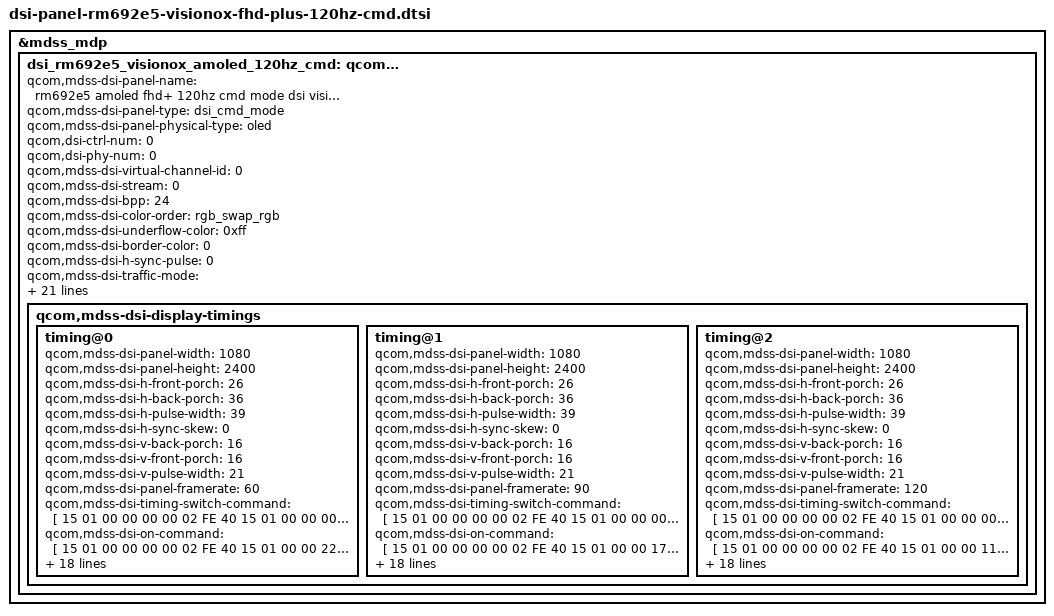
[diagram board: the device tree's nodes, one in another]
&mdss_mdp {
	dsi_rm692e5_visionox_amoled_120hz_cmd:
		qcom,mdss_dsi_rm692e5_visionox_amoled_120hz_cmd {
		qcom,mdss-dsi-panel-name =
		"rm692e5 amoled fhd+ 120hz cmd mode dsi visionox panel";
		qcom,mdss-dsi-panel-type = "dsi_cmd_mode";
		qcom,mdss-dsi-panel-physical-type = "oled";
		qcom,dsi-ctrl-num = <0>;
		qcom,dsi-phy-num = <0>;

		qcom,mdss-dsi-virtual-channel-id = <0>;
		qcom,mdss-dsi-stream = <0>;
		qcom,mdss-dsi-bpp = <24>;
		qcom,mdss-dsi-color-order = "rgb_swap_rgb";
		qcom,mdss-dsi-underflow-color = <0xff>;
		qcom,mdss-dsi-border-color = <0>;
		qcom,mdss-dsi-h-sync-pulse = <0>;
		qcom,mdss-dsi-traffic-mode = "non_burst_sync_event";
		qcom,mdss-dsi-lane-map = "lane_map_0123";
		qcom,mdss-dsi-bllp-eof-power-mode;
		qcom,mdss-dsi-bllp-power-mode;
		qcom,mdss-dsi-tx-eot-append;
		qcom,mdss-dsi-lane-0-state;
		qcom,mdss-dsi-lane-1-state;
		qcom,mdss-dsi-lane-2-state;
		qcom,mdss-dsi-lane-3-state;
		qcom,mdss-dsi-dma-trigger = "trigger_sw";
		qcom,mdss-dsi-mdp-trigger = "none";
		qcom,mdss-dsi-lp11-init;
		qcom,mdss-dsi-reset-sequence = <1 10>, <0 1>, <1 32>;
		qcom,mdss-dsi-te-pin-select = <1>;
		qcom,mdss-dsi-wr-mem-start = <0x2c>;
		qcom,mdss-dsi-wr-mem-continue = <0x3c>;
		qcom,mdss-dsi-te-dcs-command = <1>;
		qcom,mdss-dsi-te-check-enable;
		qcom,mdss-dsi-te-using-te-pin;
		qcom,fod-dim-lut = <
		/* brightness, alpha */
			0	255
			1	254
			2	253
			4	249
			6	240
			12	245
			14	243
			28	242
			42	241
			57	239
			71	238
			85	237
			100	236
			112	234
			125	233
			137	232
			150	231
			162	229
			175	228
			187	227
			200	225
			221	224
			243	223
			265	222
			286	220
			308	219
			330	218
			351	217
			373	215
			395	214
			417	213
			438	211
			460	210
			482	209
			503	208
			525	206
			547	205
			569	204
			590	203
			612	201
			634	200
			655	199
			677	197
			699	196
			721	195
			742	194
			764	192
			786	191
			807	190
			829	189
			851	187
			873	186
			894	185
			916	183
			938	182
			959	181
			981	180
			1003	178
			1024	177
			1046	176
			1068	175
			1090	173
			1111	172
			1133	171
			1155	169
			1176	168
			1198	167
			1220	166
			1242	164
			1263	163
			1285	162
			1307	161
			1328	159
			1350	158
			1372	157
			1394	155
			1415	154
			1437	153
			1459	152
			1480	150
			1502	149
			1524	148
			1546	147
			1567	145
			1589	144
			1611	143
			1632	141
			1654	140
			1676	139
			1698	138
			1719	136
			1741	135
			1763	134
			1784	133
			1806	131
			1828	130
			1849	129
			1871	127
			1893	126
			1915	125
			1936	124
			1958	122
			1980	121
			2001	120
			2023	119
			2045	117
			2067	116
			2088	115
			2110	113
			2132	112
			2153	111
			2175	110
			2197	108
			2219	107
			2240	106
			2262	105
			2284	103
			2305	102
			2327	101
			2349	99
			2371	98
			2392	97
			2414	96
			2436	94
			2457	93
			2479	92
			2501	91
			2523	89
			2544	88
			2566	87
			2588	85
			2609	84
			2631	83
			2653	82
			2674	80
			2696	79
			2718	78
			2740	77
			2761	75
			2783	74
			2805	73
			2826	71
			2848	70
			2870	69
			2892	68
			2913	66
			2935	65
			2957	64
			2978	63
			3000	61
			3022	60
			3044	59
			3065	57
			3087	56
			3109	55
			3130	54
			3152	52
			3174	51
			3196	50
			3217	49
			3239	47
			3261	46
			3282	45
			3304	43
			3326	42
			3348	41
			3369	40
			3391	38
			3413	37
			3434	36
			3456	35
			3478	33
			3499	32
			3521	31
			3541	29
		>;
		qcom,mdss-dsi-display-timings {
			timing@0 {
				qcom,mdss-dsi-panel-width = <1080>;
				qcom,mdss-dsi-panel-height = <2400>;
				qcom,mdss-dsi-h-front-porch = <26>;
				qcom,mdss-dsi-h-back-porch = <36>;
				qcom,mdss-dsi-h-pulse-width = <39>;
				qcom,mdss-dsi-h-sync-skew = <0>;
				qcom,mdss-dsi-v-back-porch = <16>;
				qcom,mdss-dsi-v-front-porch = <16>;
				qcom,mdss-dsi-v-pulse-width = <21>;
				qcom,mdss-dsi-panel-framerate = <60>;

				qcom,mdss-dsi-timing-switch-command = [
						15 01 00 00 00 00 02 FE 40
						15 01 00 00 00 00 02 BD 00
						15 01 00 00 22 00 02 FE 00
				];

				qcom,mdss-dsi-on-command = [
						15 01 00 00 00 00 02 FE 40
						15 01 00 00 22 00 02 BD 00
						15 01 00 00 00 00 02 FE D2
						15 01 00 00 00 00 02 50 11
						15 01 00 00 00 00 02 51 AB
						15 01 00 00 00 00 02 52 30
						15 01 00 00 00 00 02 53 09
						15 01 00 00 00 00 02 54 60
						15 01 00 00 00 00 02 55 04
						15 01 00 00 00 00 02 56 38
						15 01 00 00 00 00 02 58 00
						15 01 00 00 00 00 02 59 14
						15 01 00 00 00 00 02 5A 02
						15 01 00 00 00 00 02 5B 1C
						15 01 00 00 00 00 02 5C 02
						15 01 00 00 00 00 02 5D 00
						15 01 00 00 00 00 02 5E 20
						15 01 00 00 00 00 02 5F 01
						15 01 00 00 00 00 02 60 e8
						15 01 00 00 00 00 02 61 00
						15 01 00 00 00 00 02 62 07
						15 01 00 00 00 00 02 63 0C
						15 01 00 00 00 00 02 64 05
						15 01 00 00 00 00 02 65 0E
						15 01 00 00 00 00 02 66 05
						15 01 00 00 00 00 02 67 16
						15 01 00 00 00 00 02 68 18
						15 01 00 00 00 00 02 69 00
						15 01 00 00 00 00 02 6A 10
						15 01 00 00 00 00 02 6B F0
						15 01 00 00 00 00 02 6C 07
						15 01 00 00 00 00 02 6D 10
						15 01 00 00 00 00 02 6E 20
						15 01 00 00 00 00 02 6F 00
						15 01 00 00 00 00 02 70 06
						15 01 00 00 00 00 02 71 0F
						15 01 00 00 00 00 02 72 0F
						15 01 00 00 00 00 02 73 33
						15 01 00 00 00 00 02 74 0E
						15 01 00 00 00 00 02 75 1C
						15 01 00 00 00 00 02 76 2A
						15 01 00 00 00 00 02 77 38
						15 01 00 00 00 00 02 78 46
						15 01 00 00 00 00 02 79 54
						15 01 00 00 00 00 02 7A 62
						15 01 00 00 00 00 02 7B 69
						15 01 00 00 00 00 02 7C 70
						15 01 00 00 00 00 02 7D 77
						15 01 00 00 00 00 02 7E 79
						15 01 00 00 00 00 02 7F 7B
						15 01 00 00 00 00 02 80 7D
						15 01 00 00 00 00 02 81 7E
						15 01 00 00 00 00 02 82 01
						15 01 00 00 00 00 02 83 02
						15 01 00 00 00 00 02 84 22
						15 01 00 00 00 00 02 85 00
						15 01 00 00 00 00 02 86 2A
						15 01 00 00 00 00 02 87 40
						15 01 00 00 00 00 02 88 2A
						15 01 00 00 00 00 02 89 BE
						15 01 00 00 00 00 02 8A 3A
						15 01 00 00 00 00 02 8B FC
						15 01 00 00 00 00 02 8C 3A
						15 01 00 00 00 00 02 8D FA
						15 01 00 00 00 00 02 8E 3A
						15 01 00 00 00 00 02 8F F8
						15 01 00 00 00 00 02 90 3B
						15 01 00 00 00 00 02 91 38
						15 01 00 00 00 00 02 92 3B
						15 01 00 00 00 00 02 93 78
						15 01 00 00 00 00 02 94 3B
						15 01 00 00 00 00 02 95 B6
						15 01 00 00 00 00 02 96 4B
						15 01 00 00 00 00 02 97 F6
						15 01 00 00 00 00 02 98 4C
						15 01 00 00 00 00 02 99 34
						15 01 00 00 00 00 02 9A 4C
						15 01 00 00 00 00 02 9B 74
						15 01 00 00 00 00 02 9C 5C
						15 01 00 00 00 00 02 9D 74
						15 01 00 00 00 00 02 9E 8C
						15 01 00 00 00 00 02 9F F4
						15 01 00 00 00 00 02 A2 02
						15 01 00 00 00 00 02 A3 1C
						15 01 00 00 00 00 02 A4 00
						15 01 00 00 00 00 02 A5 00
						15 01 00 00 00 00 02 A6 00
						15 01 00 00 00 00 02 A7 00
						15 01 00 00 00 00 02 A9 00
						15 01 00 00 00 00 02 AA 00
						15 01 00 00 00 00 02 A0 80
						15 01 00 00 00 00 02 FE A1
						15 01 00 00 00 00 02 CD 6B
						15 01 00 00 00 00 02 CE BB
						15 01 00 00 00 00 02 FE D1
						15 01 00 00 00 00 02 B4 01
						15 01 00 00 00 00 02 FE 38
						15 01 00 00 00 00 02 17 0F
						15 01 00 00 00 00 02 18 0F
						15 01 00 00 00 00 02 FE 00
						15 01 00 00 00 00 02 FA 01
						15 01 00 00 00 00 02 C2 08
						15 01 00 00 00 00 02 35 00
						15 01 00 00 00 00 03 51 0D BB
						05 01 00 00 32 00 02 11 00
						05 01 00 00 01 00 02 29 00];
				qcom,mdss-dsi-off-command = [
						05 01 00 00 01 00 02 28 00
						05 01 00 00 01 00 02 10 00];
				qcom,mdss-dsi-on-command-state = "dsi_lp_mode";
				qcom,mdss-dsi-off-command-state = "dsi_hs_mode";

				qcom,mdss-dsi-lp1-command = [
						15 01 00 00 00 00 02 FE 00
						05 01 00 00 00 00 01 39];
				qcom,mdss-dsi-lp1-command-state = "dsi_lp_mode";
				qcom,mdss-dsi-nolp-command = [
						15 01 00 00 00 00 02 FE 00
						05 01 00 00 00 00 01 38];
				qcom,mdss-dsi-nolp-command-state = "dsi_lp_mode";

				qcom,mdss-dsi-h-sync-pulse = <0>;
				qcom,compression-mode = "dsc";
				qcom,mdss-dsc-slice-height = <20>;
				qcom,mdss-dsc-slice-width = <540>;
				qcom,mdss-dsc-slice-per-pkt = <2>;
				qcom,mdss-dsc-bit-per-component = <10>;
				qcom,mdss-dsc-bit-per-pixel = <8>;
				qcom,mdss-dsc-block-prediction-enable;
			};
			timing@1 {
				qcom,mdss-dsi-panel-width = <1080>;
				qcom,mdss-dsi-panel-height = <2400>;
				qcom,mdss-dsi-h-front-porch = <26>;
				qcom,mdss-dsi-h-back-porch = <36>;
				qcom,mdss-dsi-h-pulse-width = <39>;
				qcom,mdss-dsi-h-sync-skew = <0>;
				qcom,mdss-dsi-v-back-porch = <16>;
				qcom,mdss-dsi-v-front-porch = <16>;
				qcom,mdss-dsi-v-pulse-width = <21>;
				qcom,mdss-dsi-panel-framerate = <90>;

				qcom,mdss-dsi-timing-switch-command = [
						15 01 00 00 00 00 02 FE 40
						15 01 00 00 00 00 02 BD 06
						15 01 00 00 17 00 02 FE 00
				];

				qcom,mdss-dsi-on-command = [
						15 01 00 00 00 00 02 FE 40
						15 01 00 00 17 00 02 BD 06
						15 01 00 00 00 00 02 FE D2
						15 01 00 00 00 00 02 50 11
						15 01 00 00 00 00 02 51 AB
						15 01 00 00 00 00 02 52 30
						15 01 00 00 00 00 02 53 09
						15 01 00 00 00 00 02 54 60
						15 01 00 00 00 00 02 55 04
						15 01 00 00 00 00 02 56 38
						15 01 00 00 00 00 02 58 00
						15 01 00 00 00 00 02 59 14
						15 01 00 00 00 00 02 5A 02
						15 01 00 00 00 00 02 5B 1C
						15 01 00 00 00 00 02 5C 02
						15 01 00 00 00 00 02 5D 00
						15 01 00 00 00 00 02 5E 20
						15 01 00 00 00 00 02 5F 01
						15 01 00 00 00 00 02 60 e8
						15 01 00 00 00 00 02 61 00
						15 01 00 00 00 00 02 62 07
						15 01 00 00 00 00 02 63 0C
						15 01 00 00 00 00 02 64 05
						15 01 00 00 00 00 02 65 0E
						15 01 00 00 00 00 02 66 05
						15 01 00 00 00 00 02 67 16
						15 01 00 00 00 00 02 68 18
						15 01 00 00 00 00 02 69 00
						15 01 00 00 00 00 02 6A 10
						15 01 00 00 00 00 02 6B F0
						15 01 00 00 00 00 02 6C 07
						15 01 00 00 00 00 02 6D 10
						15 01 00 00 00 00 02 6E 20
						15 01 00 00 00 00 02 6F 00
						15 01 00 00 00 00 02 70 06
						15 01 00 00 00 00 02 71 0F
						15 01 00 00 00 00 02 72 0F
						15 01 00 00 00 00 02 73 33
						15 01 00 00 00 00 02 74 0E
						15 01 00 00 00 00 02 75 1C
						15 01 00 00 00 00 02 76 2A
						15 01 00 00 00 00 02 77 38
						15 01 00 00 00 00 02 78 46
						15 01 00 00 00 00 02 79 54
						15 01 00 00 00 00 02 7A 62
						15 01 00 00 00 00 02 7B 69
						15 01 00 00 00 00 02 7C 70
						15 01 00 00 00 00 02 7D 77
						15 01 00 00 00 00 02 7E 79
						15 01 00 00 00 00 02 7F 7B
						15 01 00 00 00 00 02 80 7D
						15 01 00 00 00 00 02 81 7E
						15 01 00 00 00 00 02 82 01
						15 01 00 00 00 00 02 83 02
						15 01 00 00 00 00 02 84 22
						15 01 00 00 00 00 02 85 00
						15 01 00 00 00 00 02 86 2A
						15 01 00 00 00 00 02 87 40
						15 01 00 00 00 00 02 88 2A
						15 01 00 00 00 00 02 89 BE
						15 01 00 00 00 00 02 8A 3A
						15 01 00 00 00 00 02 8B FC
						15 01 00 00 00 00 02 8C 3A
						15 01 00 00 00 00 02 8D FA
						15 01 00 00 00 00 02 8E 3A
						15 01 00 00 00 00 02 8F F8
						15 01 00 00 00 00 02 90 3B
						15 01 00 00 00 00 02 91 38
						15 01 00 00 00 00 02 92 3B
						15 01 00 00 00 00 02 93 78
						15 01 00 00 00 00 02 94 3B
						15 01 00 00 00 00 02 95 B6
						15 01 00 00 00 00 02 96 4B
						15 01 00 00 00 00 02 97 F6
						15 01 00 00 00 00 02 98 4C
						15 01 00 00 00 00 02 99 34
						15 01 00 00 00 00 02 9A 4C
						15 01 00 00 00 00 02 9B 74
						15 01 00 00 00 00 02 9C 5C
						15 01 00 00 00 00 02 9D 74
						15 01 00 00 00 00 02 9E 8C
						15 01 00 00 00 00 02 9F F4
						15 01 00 00 00 00 02 A2 02
						15 01 00 00 00 00 02 A3 1C
						15 01 00 00 00 00 02 A4 00
						15 01 00 00 00 00 02 A5 00
						15 01 00 00 00 00 02 A6 00
						15 01 00 00 00 00 02 A7 00
						15 01 00 00 00 00 02 A9 00
						15 01 00 00 00 00 02 AA 00
						15 01 00 00 00 00 02 A0 80
						15 01 00 00 00 00 02 FE A1
						15 01 00 00 00 00 02 CD 6B
						15 01 00 00 00 00 02 CE BB
						15 01 00 00 00 00 02 FE D1
						15 01 00 00 00 00 02 B4 01
						15 01 00 00 00 00 02 FE 38
						15 01 00 00 00 00 02 17 0F
						15 01 00 00 00 00 02 18 0F
						15 01 00 00 00 00 02 FE 00
						15 01 00 00 00 00 02 FA 01
						15 01 00 00 00 00 02 C2 08
						15 01 00 00 00 00 02 35 00
						15 01 00 00 00 00 03 51 0D BB
						05 01 00 00 32 00 02 11 00
						05 01 00 00 01 00 02 29 00];
				qcom,mdss-dsi-off-command = [
						05 01 00 00 01 00 02 28 00
						05 01 00 00 01 00 02 10 00];
				qcom,mdss-dsi-on-command-state = "dsi_lp_mode";
				qcom,mdss-dsi-off-command-state = "dsi_hs_mode";

				qcom,mdss-dsi-lp1-command = [
						15 01 00 00 00 00 02 FE 00
						05 01 00 00 00 00 01 39];
				qcom,mdss-dsi-lp1-command-state = "dsi_lp_mode";
				qcom,mdss-dsi-nolp-command = [
						15 01 00 00 00 00 02 FE 00
						05 01 00 00 00 00 01 38];
				qcom,mdss-dsi-nolp-command-state = "dsi_lp_mode";

				qcom,mdss-dsi-h-sync-pulse = <0>;
				qcom,compression-mode = "dsc";
				qcom,mdss-dsc-slice-height = <20>;
				qcom,mdss-dsc-slice-width = <540>;
				qcom,mdss-dsc-slice-per-pkt = <2>;
				qcom,mdss-dsc-bit-per-component = <10>;
				qcom,mdss-dsc-bit-per-pixel = <8>;
				qcom,mdss-dsc-block-prediction-enable;
			};
			timing@2 {
				qcom,mdss-dsi-panel-width = <1080>;
				qcom,mdss-dsi-panel-height = <2400>;
				qcom,mdss-dsi-h-front-porch = <26>;
				qcom,mdss-dsi-h-back-porch = <36>;
				qcom,mdss-dsi-h-pulse-width = <39>;
				qcom,mdss-dsi-h-sync-skew = <0>;
				qcom,mdss-dsi-v-back-porch = <16>;
				qcom,mdss-dsi-v-front-porch = <16>;
				qcom,mdss-dsi-v-pulse-width = <21>;
				qcom,mdss-dsi-panel-framerate = <120>;

				qcom,mdss-dsi-timing-switch-command = [
						15 01 00 00 00 00 02 FE 40
						15 01 00 00 00 00 02 BD 07
						15 01 00 00 11 00 02 FE 00
				];

				qcom,mdss-dsi-on-command = [
						15 01 00 00 00 00 02 FE 40
						15 01 00 00 11 00 02 BD 07
						15 01 00 00 00 00 02 FE D2
						15 01 00 00 00 00 02 50 11
						15 01 00 00 00 00 02 51 AB
						15 01 00 00 00 00 02 52 30
						15 01 00 00 00 00 02 53 09
						15 01 00 00 00 00 02 54 60
						15 01 00 00 00 00 02 55 04
						15 01 00 00 00 00 02 56 38
						15 01 00 00 00 00 02 58 00
						15 01 00 00 00 00 02 59 14
						15 01 00 00 00 00 02 5A 02
						15 01 00 00 00 00 02 5B 1C
						15 01 00 00 00 00 02 5C 02
						15 01 00 00 00 00 02 5D 00
						15 01 00 00 00 00 02 5E 20
						15 01 00 00 00 00 02 5F 01
						15 01 00 00 00 00 02 60 e8
						15 01 00 00 00 00 02 61 00
						15 01 00 00 00 00 02 62 07
						15 01 00 00 00 00 02 63 0C
						15 01 00 00 00 00 02 64 05
						15 01 00 00 00 00 02 65 0E
						15 01 00 00 00 00 02 66 05
						15 01 00 00 00 00 02 67 16
						15 01 00 00 00 00 02 68 18
						15 01 00 00 00 00 02 69 00
						15 01 00 00 00 00 02 6A 10
						15 01 00 00 00 00 02 6B F0
						15 01 00 00 00 00 02 6C 07
						15 01 00 00 00 00 02 6D 10
						15 01 00 00 00 00 02 6E 20
						15 01 00 00 00 00 02 6F 00
						15 01 00 00 00 00 02 70 06
						15 01 00 00 00 00 02 71 0F
						15 01 00 00 00 00 02 72 0F
						15 01 00 00 00 00 02 73 33
						15 01 00 00 00 00 02 74 0E
						15 01 00 00 00 00 02 75 1C
						15 01 00 00 00 00 02 76 2A
						15 01 00 00 00 00 02 77 38
						15 01 00 00 00 00 02 78 46
						15 01 00 00 00 00 02 79 54
						15 01 00 00 00 00 02 7A 62
						15 01 00 00 00 00 02 7B 69
						15 01 00 00 00 00 02 7C 70
						15 01 00 00 00 00 02 7D 77
						15 01 00 00 00 00 02 7E 79
						15 01 00 00 00 00 02 7F 7B
						15 01 00 00 00 00 02 80 7D
						15 01 00 00 00 00 02 81 7E
						15 01 00 00 00 00 02 82 01
						15 01 00 00 00 00 02 83 02
						15 01 00 00 00 00 02 84 22
						15 01 00 00 00 00 02 85 00
						15 01 00 00 00 00 02 86 2A
						15 01 00 00 00 00 02 87 40
						15 01 00 00 00 00 02 88 2A
						15 01 00 00 00 00 02 89 BE
						15 01 00 00 00 00 02 8A 3A
						15 01 00 00 00 00 02 8B FC
						15 01 00 00 00 00 02 8C 3A
						15 01 00 00 00 00 02 8D FA
						15 01 00 00 00 00 02 8E 3A
						15 01 00 00 00 00 02 8F F8
						15 01 00 00 00 00 02 90 3B
						15 01 00 00 00 00 02 91 38
						15 01 00 00 00 00 02 92 3B
						15 01 00 00 00 00 02 93 78
						15 01 00 00 00 00 02 94 3B
						15 01 00 00 00 00 02 95 B6
						15 01 00 00 00 00 02 96 4B
						15 01 00 00 00 00 02 97 F6
						15 01 00 00 00 00 02 98 4C
						15 01 00 00 00 00 02 99 34
						15 01 00 00 00 00 02 9A 4C
						15 01 00 00 00 00 02 9B 74
						15 01 00 00 00 00 02 9C 5C
						15 01 00 00 00 00 02 9D 74
						15 01 00 00 00 00 02 9E 8C
						15 01 00 00 00 00 02 9F F4
						15 01 00 00 00 00 02 A2 02
						15 01 00 00 00 00 02 A3 1C
						15 01 00 00 00 00 02 A4 00
						15 01 00 00 00 00 02 A5 00
						15 01 00 00 00 00 02 A6 00
						15 01 00 00 00 00 02 A7 00
						15 01 00 00 00 00 02 A9 00
						15 01 00 00 00 00 02 AA 00
						15 01 00 00 00 00 02 A0 80
						15 01 00 00 00 00 02 FE A1
						15 01 00 00 00 00 02 CD 6B
						15 01 00 00 00 00 02 CE BB
						15 01 00 00 00 00 02 FE D1
						15 01 00 00 00 00 02 B4 01
						15 01 00 00 00 00 02 FE 38
						15 01 00 00 00 00 02 17 0F
						15 01 00 00 00 00 02 18 0F
						15 01 00 00 00 00 02 FE 00
						15 01 00 00 00 00 02 FA 01
						15 01 00 00 00 00 02 C2 08
						15 01 00 00 00 00 02 35 00
						15 01 00 00 00 00 03 51 0D BB
						05 01 00 00 32 00 02 11 00
						05 01 00 00 01 00 02 29 00];
				qcom,mdss-dsi-off-command = [
						05 01 00 00 01 00 02 28 00
						05 01 00 00 01 00 02 10 00];
				qcom,mdss-dsi-on-command-state = "dsi_lp_mode";
				qcom,mdss-dsi-off-command-state = "dsi_hs_mode";

				qcom,mdss-dsi-lp1-command = [
						15 01 00 00 00 00 02 FE 00
						05 01 00 00 00 00 01 39];
				qcom,mdss-dsi-lp1-command-state = "dsi_lp_mode";
				qcom,mdss-dsi-nolp-command = [
						15 01 00 00 00 00 02 FE 00
						05 01 00 00 00 00 01 38];
				qcom,mdss-dsi-nolp-command-state = "dsi_lp_mode";

				qcom,mdss-dsi-h-sync-pulse = <0>;
				qcom,compression-mode = "dsc";
				qcom,mdss-dsc-slice-height = <20>;
				qcom,mdss-dsc-slice-width = <540>;
				qcom,mdss-dsc-slice-per-pkt = <2>;
				qcom,mdss-dsc-bit-per-component = <10>;
				qcom,mdss-dsc-bit-per-pixel = <8>;
				qcom,mdss-dsc-block-prediction-enable;
			};
		};
	};
};
